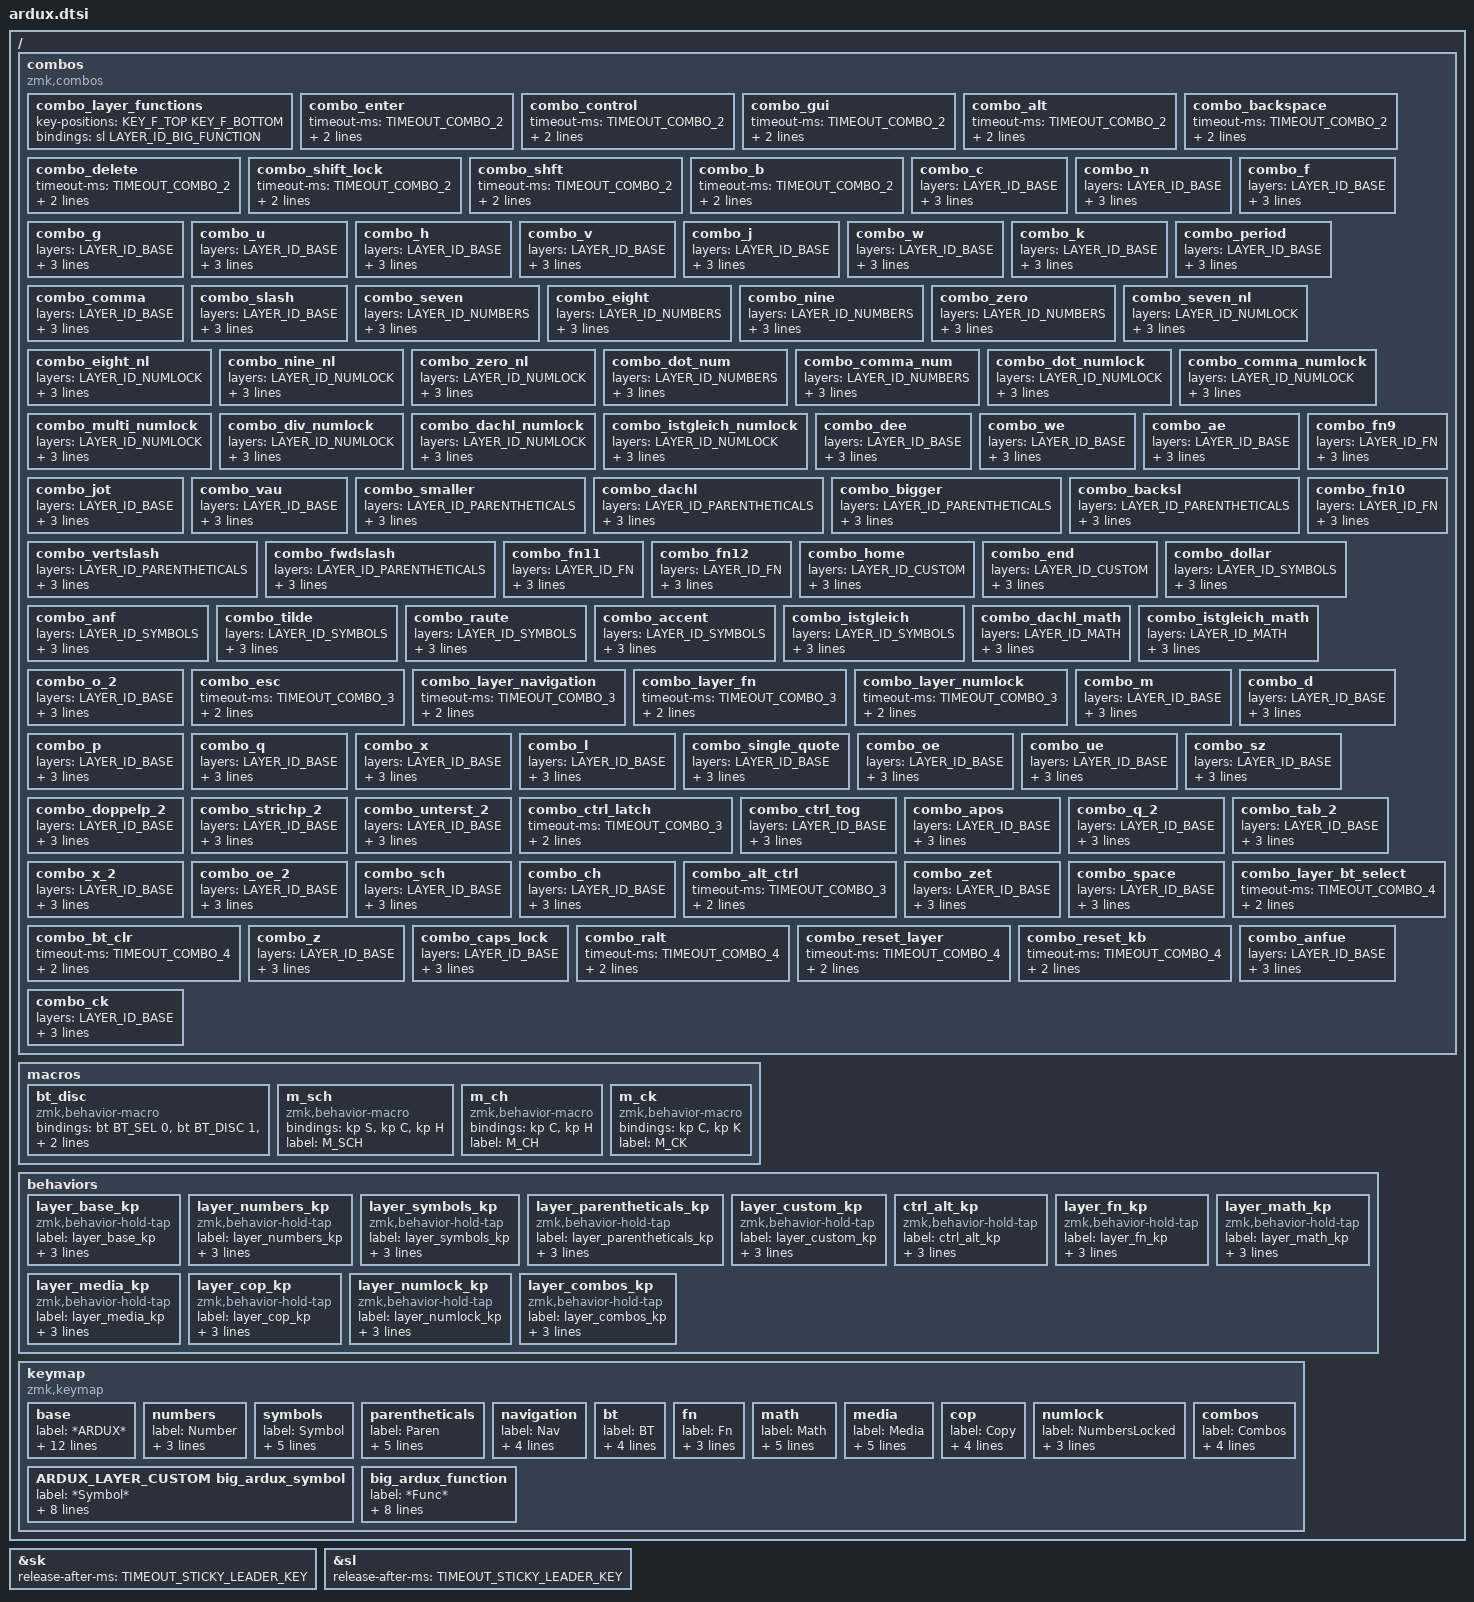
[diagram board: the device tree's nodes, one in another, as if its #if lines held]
/*
 * Copyright (c) 2021 Mike "KemoNine" Crosson
 *meins meins meins
 * SPDX-License-Identifier: MIT
 */

#include <behaviors.dtsi>
#include <dt-bindings/zmk/keys.h>
#include <dt-bindings/zmk/outputs.h>

/*****************************************
 * Macros for filling in "&none" in the right places in the keymap for re-use needs
 *****************************************/
#define NONE0(X)
#define NONE1(X) X
#define NONE2(X) NONE1(X) X
#define NONE3(X) NONE2(X) X
#define NONE4(X) NONE3(X) X
#define NONE5(X) NONE4(X) X
#define NONE6(X) NONE5(X) X
#define NONE7(X) NONE6(X) X
#define NONE8(X) NONE7(X) X
#define NONE9(X) NONE8(X) X
#define NONE10(X) NONE9(X) X

#define NONE(HUNDREDS,TENS,ONES) \
  NONE##HUNDREDS(NONE10(NONE10(&none))) \
  NONE##TENS(NONE10(&none)) \
  NONE##ONES(&none)

/*****************************************
 * ARDUX website : https://www.ardux.io
 * Primary reference : https://www.ardux.io/_FILES/images/ARDUX.jpg
*****************************************/

/*****************************************
 * Setting up ARDUX comboing
 *   - Enabled right OR left handed orientation
 *   - Please note: A/E key positions should be on your INDEX finger
 *     - The online reference is for right handed use
 *     - When using the ARDUX layout left handed you'll want to ensure your keypositions are flipped along the Y axis
 *   - Update/adjust the key positions using your boards keymap 
 *     - See below for additional details
 *   - YOU MUST SET THE FOLLOWING CONFIG VALUES FOR THIS SETUP TO WORK PROPERLY IN YOUR BOARDS .conf FILE
 *     - CONFIG_ZMK_COMBO_MAX_COMBOS_PER_KEY=16
 *     - CONFIG_ZMK_COMBO_MAX_KEYS_PER_COMBO=8
 *     - CONFIG_ZMK_COMBO_MAX_PRESSED_COMBOS=8
 *****************************************/

/*****************************************
 * Define which layout you want to use
 *  ONLY ENABLE ONE OF THESE
*****************************************/
//#define ARDUX_RIGHT 1
//#define ARDUX_LEFT 1
//#define ARDUX_BIG 1
// If you use COLEMAK as your standard keyboard layout, you may want this
//     This define will make base ardux keys and N more in line with COLEMAK
//#define ARDUX_COLEMAK 1

/*****************************************
 * Define key positions used for combos
 * These definitions are used to define the various ARDUX combos
 * 
 * Please see the documentation on "combos" for details on how to find the proper key positions
 *
 * Default key positions are for a generic 4x2 keyboard and should NOT be used outright
 * DEFINE these definitions in your boards keymap BEFORE including ardux.dtsi
*****************************************/
// ARTS Row
// #define KEY_A 0
// #define KEY_R 1
// #define KEY_T 2
// #define KEY_S 3
// EYIO Row
// #define KEY_E 4
// #define KEY_Y 5
// #define KEY_I 6
// #define KEY_O 7
// Big ardux F1-12 layer keys for combo
// #define KEY_F_TOP -1
// #define KEY_F_BOTTOM -1

/*****************************************
 * Define key position offsets in main keymap
 *
 * In order to make this keymap flexible, you must setup the number of &none "offsets" to use
 * The defines below should be set in your LOCAL keymap and using the above "NONE([hundreds],[tens],[ones])" macro for filling in the gaps
*****************************************/
// #define LEADING_NONES NONE(0, 1, 0)
// #define MIDDLE_NONES NONE(0, 0, 3)
// #define TRAILING_NONES NONE(0, 1, 0)
// #define BIG_LEADING_NONES NONE(0, 0, 0)
// #define BIG_BETWEEN_ROW_ONE_TWO_NONES NONE(0, 0, 0)
// #define BIG_BETWEEN_ROW_TWO_THREE_NONES NONE(0, 0, 0)
// #define BIG_BETWEEN_ROW_THREE_THUMBS NONE(0, 0, 0)
// #define BIG_TRAILING_NONES NONE(0, 0, 0)

/*****************************************
 * Define custom BT layer extra keys
 *
 * You can override the 2 blank keys on the BT select layer by copy/pasting the below into your keymap
 *     *before* including the ardux.dtsfile
 * Once added to your keymap you can adjust these 2 keys as you see fit
*****************************************/
#if !defined ARDUX_BT_TOP
#define ARDUX_BT_TOP &out OUT_BLE
#endif
#if !defined ARDUX_BT_BOTTOM
#define ARDUX_BT_BOTTOM &out OUT_USB
#endif

/*****************************************
 * Define how long it takes for the combos/holds to 'time out'
 * See documentation on "combos" for more detail
 * THE COMBO TIMEOUTS MUST BE THE SAME
 *    https://github.com/zmkfirmware/zmk/issues/905
 *****************************************/
#if !defined TIMEOUT_COMBO_2
#define TIMEOUT_COMBO_2 75
#endif
#if !defined TIMEOUT_COMBO_3
#define TIMEOUT_COMBO_3 125
#endif
#if !defined TIMEOUT_COMBO_4
#define TIMEOUT_COMBO_4 150
#endif
#if !defined TIMEOUT_LAYER_HOLD
#define TIMEOUT_LAYER_HOLD 200
#endif
#if !defined TIMEOUT_STICKY_LEADER_KEY
#define TIMEOUT_STICKY_LEADER_KEY 2500
#endif
&sk {
	release-after-ms = <TIMEOUT_STICKY_LEADER_KEY>;
};
&sl { 
	release-after-ms = <TIMEOUT_STICKY_LEADER_KEY>;
};

/*****************************************
 * Define custom layer
 *
 * You can override this layer by copy/pasting the into your keymap *before* including the ardux.dtsi file
 * Once added to your keymap you can adjust as you see fit
*****************************************/
#if !defined ARDUX_LAYER_CUSTOM
#if defined ARDUX_RIGHT
#define ARDUX_LAYER_CUSTOM                                            \
		custom {                                                       \
			label = "Custom";                                          \
			bindings = <                                               \
				LEADING_NONES                                          \
				&kp LC(LEFT)     &kp UP    &kp LC(RIGHT)  &none              \
				MIDDLE_NONES                                           \
				&kp LEFT     &kp DOWN  &kp RIGHT  &mo LAYER_ID_CUSTOM \
				TRAILING_NONES                                         \
			>;                                                         \
		};
		
#endif
#if defined ARDUX_LEFT
#define ARDUX_LAYER_CUSTOM                                            \
		custom {                                                       \
			label = "Custom";                                          \
			bindings = <                                               \
				LEADING_NONES                                          \
				&kp LC(RIGHT)     &kp UP   &kp LC(LEFT)   &none              \
				MIDDLE_NONES                                           \
				&kp RIGHT     &kp DOWN  &kp LEFT  &mo LAYER_ID_CUSTOM \
				TRAILING_NONES                                         \
			>;                                                         \
		};
#endif
#endif

/*****************************************
 * Define base layer chars for 'standard ARDUX' or 'COLEMAK' inspired (you can add more by following the pattern below)
 * Turn on the ARDUX_COLEMAK definition above if you want this change
 *****************************************/
#define ARDUX_BASE_A A
#define ARDUX_BASE_R T
#define ARDUX_BASE_T R
#define ARDUX_BASE_S D
#define ARDUX_BASE_E E
#define ARDUX_BASE_Y N
#define ARDUX_BASE_I I
#define ARDUX_BASE_O S
#define ARDUX_COMBO_N Z
#if ARDUX_COLEMAK
#define ARDUX_BASE_A T
#define ARDUX_BASE_R S
#define ARDUX_BASE_T R
#define ARDUX_BASE_S A
#define ARDUX_BASE_E N
#define ARDUX_BASE_Y E
#define ARDUX_BASE_I I
#define ARDUX_BASE_O O
#define ARDUX_COMBO_N Y
#endif

/*****************************************
 * Layer IDs used by the ARDUX keymap
 * Do NOT change these and do NOT change the order of the layers as shown below
 *****************************************/
#define LAYER_ID_GLOBAL -1
#define LAYER_ID_BASE 0
#define LAYER_ID_NUMBERS 1
#define LAYER_ID_SYMBOLS 2
#define LAYER_ID_PARENTHETICALS 3
#define LAYER_ID_NAVIGATION 4
#define LAYER_ID_BT_SEL 5
#define LAYER_ID_FN 6
#define LAYER_ID_MATH 7
#define LAYER_ID_MEDIA 8
#define LAYER_ID_COP 9
#define LAYER_ID_NUMLOCK 10
#define LAYER_ID_COMBOS 11
#define LAYER_ID_CUSTOM 12
#define LAYER_ID_BIG_SYM 13
#define LAYER_ID_BIG_FUNCTION 14



/*****************************************
 * Standard ARDUX combo definitions
 * These should NOT be changed and are global in scope
 *****************************************/
/ {
	combos {
		compatible = "zmk,combos";
		/*****************************************
		 * 2 key combos
		 *****************************************/
		// Function layer doesn't apply to non-big ardux presently
		#if defined ARDUX_BIG
		combo_layer_functions { key-positions = <KEY_F_TOP KEY_F_BOTTOM>; bindings = <&sl LAYER_ID_BIG_FUNCTION>; };
		#endif
		combo_enter      { timeout-ms = <TIMEOUT_COMBO_2>; key-positions = <KEY_A KEY_E>; bindings = <&kp ENTER>; };
		combo_control    { timeout-ms = <TIMEOUT_COMBO_2>; key-positions = <KEY_E KEY_S>; bindings = <&sk LCTRL>; };
		combo_gui        { timeout-ms = <TIMEOUT_COMBO_2>; key-positions = <KEY_Y KEY_S>; bindings = <&sk LGUI>; };
		combo_alt        { timeout-ms = <TIMEOUT_COMBO_2>; key-positions = <KEY_I KEY_S>; bindings = <&sk LALT>; };
		combo_backspace  { timeout-ms = <TIMEOUT_COMBO_2>; key-positions = <KEY_E KEY_R>; bindings = <&kp BACKSPACE>; };
		combo_delete     { timeout-ms = <TIMEOUT_COMBO_2>; key-positions = <KEY_I KEY_R>; bindings = <&kp DELETE>; };
		combo_shift_lock { timeout-ms = <TIMEOUT_COMBO_2>; key-positions = <KEY_R KEY_Y>; bindings = <&kt LSHFT>; };
		

		combo_shft        { timeout-ms = <TIMEOUT_COMBO_2>; key-positions = <KEY_T KEY_I>; bindings = <&sk LSHFT>; };

		combo_b           { timeout-ms = <TIMEOUT_COMBO_2>; key-positions = <KEY_E KEY_O>; bindings = <&kp SPACE>; };
		combo_c           { layers = <LAYER_ID_BASE>; timeout-ms = <TIMEOUT_COMBO_2>; key-positions = <KEY_E KEY_Y>; bindings = <&kp C>; };
		combo_n           { layers = <LAYER_ID_BASE>; timeout-ms = <TIMEOUT_COMBO_2>; key-positions = <KEY_I KEY_O>; bindings = <&kp ARDUX_COMBO_N>; };
		combo_f           { layers = <LAYER_ID_BASE>; timeout-ms = <TIMEOUT_COMBO_2>; key-positions = <KEY_A KEY_R>; bindings = <&kp F>; };
		combo_g           { layers = <LAYER_ID_BASE>; timeout-ms = <TIMEOUT_COMBO_2>; key-positions = <KEY_R KEY_T>; bindings = <&kp G>; };
		combo_u           { layers = <LAYER_ID_BASE>; timeout-ms = <TIMEOUT_COMBO_2>; key-positions = <KEY_Y KEY_I>; bindings = <&kp U>; };
		combo_h           { layers = <LAYER_ID_BASE>; timeout-ms = <TIMEOUT_COMBO_2>; key-positions = <KEY_E KEY_I>; bindings = <&kp H>; };
		combo_v           { layers = <LAYER_ID_BASE>; timeout-ms = <TIMEOUT_COMBO_2>; key-positions = <KEY_R KEY_S>; bindings = <&kp V>; };
		combo_j           { layers = <LAYER_ID_BASE>; timeout-ms = <TIMEOUT_COMBO_2>; key-positions = <KEY_T KEY_S>; bindings = <&kp J>; };
		combo_w           { layers = <LAYER_ID_BASE>; timeout-ms = <TIMEOUT_COMBO_2>; key-positions = <KEY_A KEY_S>; bindings = <&kp W>; };
		combo_k           { layers = <LAYER_ID_BASE>; timeout-ms = <TIMEOUT_COMBO_2>; key-positions = <KEY_Y KEY_O>; bindings = <&kp K>; };
		combo_period      { layers = <LAYER_ID_BASE>; timeout-ms = <TIMEOUT_COMBO_2>; key-positions = <KEY_A KEY_Y>; bindings = <&kp DOT>; };
		combo_comma       { layers = <LAYER_ID_BASE>; timeout-ms = <TIMEOUT_COMBO_2>; key-positions = <KEY_A KEY_I>; bindings = <&kp COMMA>; };
		combo_slash       { layers = <LAYER_ID_BASE>; timeout-ms = <TIMEOUT_COMBO_2>; key-positions = <KEY_A KEY_O>; bindings = <&kp SLASH>; };
		// combo_exclamation { layers = <LAYER_ID_BASE>; timeout-ms = <TIMEOUT_COMBO_2>; key-positions = <KEY_T KEY_I>; bindings = <&kp EXCL>; };
		//combo_apost       { layers = <LAYER_ID_BASE>; timeout-ms = <TIMEOUT_COMBO_2>; key-positions = <KEY_T KEY_E>; bindings = <&kp LS(NON_US_HASH)>; };
		
		combo_seven { layers = <LAYER_ID_NUMBERS>; timeout-ms = <TIMEOUT_COMBO_2>; key-positions = <KEY_A KEY_R>; bindings = <&kp N7>; };
		combo_eight { layers = <LAYER_ID_NUMBERS>; timeout-ms = <TIMEOUT_COMBO_2>; key-positions = <KEY_R KEY_T>; bindings = <&kp N8>; };
		combo_nine  { layers = <LAYER_ID_NUMBERS>; timeout-ms = <TIMEOUT_COMBO_2>; key-positions = <KEY_E KEY_Y>; bindings = <&kp N9>; };
		combo_zero  { layers = <LAYER_ID_NUMBERS>; timeout-ms = <TIMEOUT_COMBO_2>; key-positions = <KEY_Y KEY_I>; bindings = <&kp N0>; };

		combo_seven_nl { layers = <LAYER_ID_NUMLOCK>; timeout-ms = <TIMEOUT_COMBO_2>; key-positions = <KEY_A KEY_R>; bindings = <&kp N7>; };
		combo_eight_nl { layers = <LAYER_ID_NUMLOCK>; timeout-ms = <TIMEOUT_COMBO_2>; key-positions = <KEY_R KEY_T>; bindings = <&kp N8>; };
		combo_nine_nl  { layers = <LAYER_ID_NUMLOCK>; timeout-ms = <TIMEOUT_COMBO_2>; key-positions = <KEY_E KEY_Y>; bindings = <&kp N9>; };
		combo_zero_nl  { layers = <LAYER_ID_NUMLOCK>; timeout-ms = <TIMEOUT_COMBO_2>; key-positions = <KEY_Y KEY_I>; bindings = <&kp N0>; };

		combo_dot_num   { layers = <LAYER_ID_NUMBERS>; timeout-ms = <TIMEOUT_COMBO_2>; key-positions = <KEY_A KEY_T>; bindings = <&kp DOT>; };
		combo_comma_num { layers = <LAYER_ID_NUMBERS>; timeout-ms = <TIMEOUT_COMBO_2>; key-positions = <KEY_E KEY_I>; bindings = <&kp COMMA>; };

		combo_dot_numlock   { layers = <LAYER_ID_NUMLOCK>; timeout-ms = <TIMEOUT_COMBO_2>; key-positions = <KEY_A KEY_T>; bindings = <&kp DOT>; };
		combo_comma_numlock { layers = <LAYER_ID_NUMLOCK>; timeout-ms = <TIMEOUT_COMBO_2>; key-positions = <KEY_E KEY_I>; bindings = <&kp COMMA>; };
		combo_multi_numlock { layers = <LAYER_ID_NUMLOCK>; timeout-ms = <TIMEOUT_COMBO_2>; key-positions = <KEY_T KEY_S>; bindings = <&kp KP_MULTIPLY>; };
		combo_div_numlock { layers = <LAYER_ID_NUMLOCK>; timeout-ms = <TIMEOUT_COMBO_2>; key-positions = <KEY_I KEY_O>; bindings = <&kp KP_DIVIDE>; };
		combo_dachl_numlock { layers = <LAYER_ID_NUMLOCK>; timeout-ms = <TIMEOUT_COMBO_2>; key-positions = <KEY_R KEY_S>; bindings = <&kp GRAVE>; };
		combo_istgleich_numlock { layers = <LAYER_ID_NUMLOCK>; timeout-ms = <TIMEOUT_COMBO_2>; key-positions = <KEY_Y KEY_O>; bindings = <&kp LS(N0)>; };

		combo_dee     { layers = <LAYER_ID_BASE>; timeout-ms = <TIMEOUT_COMBO_2>; key-positions = <KEY_A KEY_T>; bindings = <&kp D>; };
		combo_we     { layers = <LAYER_ID_BASE>; timeout-ms = <TIMEOUT_COMBO_2>; key-positions = <KEY_E KEY_T>; bindings = <&kp W>; };
		combo_ae     { layers = <LAYER_ID_BASE>; timeout-ms = <TIMEOUT_COMBO_2>; key-positions = <KEY_Y KEY_T>; bindings = <&kp APOS>; };
		combo_jot     { layers = <LAYER_ID_BASE>; timeout-ms = <TIMEOUT_COMBO_2>; key-positions = <KEY_O KEY_T>; bindings = <&kp J>; };
		combo_vau     { layers = <LAYER_ID_BASE>; timeout-ms = <TIMEOUT_COMBO_2>; key-positions = <KEY_R KEY_O>; bindings = <&kp V>; };

		combo_smaller   { layers = <LAYER_ID_PARENTHETICALS>; timeout-ms = <TIMEOUT_COMBO_2>; key-positions = <KEY_R KEY_T>; bindings = <&kp NON_US_BACKSLASH>; };
		combo_dachl   { layers = <LAYER_ID_PARENTHETICALS>; timeout-ms = <TIMEOUT_COMBO_2>; key-positions = <KEY_R KEY_S>; bindings = <&kp GRAVE>; };
		combo_bigger   { layers = <LAYER_ID_PARENTHETICALS>; timeout-ms = <TIMEOUT_COMBO_2>; key-positions = <KEY_I KEY_Y>; bindings = <&kp LS(NON_US_BACKSLASH)>; };

		combo_backsl   { layers = <LAYER_ID_PARENTHETICALS>; timeout-ms = <TIMEOUT_COMBO_2>; key-positions = <KEY_I KEY_O>; bindings = <&kp RA(MINUS)>; };
		combo_vertslash   { layers = <LAYER_ID_PARENTHETICALS>; timeout-ms = <TIMEOUT_COMBO_2>; key-positions = <KEY_Y KEY_O>; bindings = <&kp RA(NON_US_BACKSLASH)>; };
		combo_fwdslash   { layers = <LAYER_ID_PARENTHETICALS>; timeout-ms = <TIMEOUT_COMBO_2>; key-positions = <KEY_T KEY_S>; bindings = <&kp LS(N7)>; };

		combo_fn9    { layers = <LAYER_ID_FN>; timeout-ms = <TIMEOUT_COMBO_2>; key-positions = <KEY_A KEY_R>; bindings = <&kp F9>; };
		combo_fn10   { layers = <LAYER_ID_FN>; timeout-ms = <TIMEOUT_COMBO_2>; key-positions = <KEY_R KEY_T>; bindings = <&kp F10>; };
		combo_fn11   { layers = <LAYER_ID_FN>; timeout-ms = <TIMEOUT_COMBO_2>; key-positions = <KEY_T KEY_S>; bindings = <&kp F11>; };
		combo_fn12   { layers = <LAYER_ID_FN>; timeout-ms = <TIMEOUT_COMBO_2>; key-positions = <KEY_E KEY_Y>; bindings = <&kp F12>; };


		#if defined ARDUX_RIGHT
		combo_home   { layers = <LAYER_ID_CUSTOM>; timeout-ms = <TIMEOUT_COMBO_2>; key-positions = <KEY_A KEY_R>; bindings = <&kp HOME>; };
		combo_end   { layers = <LAYER_ID_CUSTOM>; timeout-ms = <TIMEOUT_COMBO_2>; key-positions = <KEY_R KEY_T>; bindings = <&kp END>; };
		#endif
		#if defined ARDUX_LEFT
		combo_home   { layers = <LAYER_ID_CUSTOM>; timeout-ms = <TIMEOUT_COMBO_2>; key-positions = <KEY_T KEY_R>; bindings = <&kp HOME>; };
		combo_end   { layers = <LAYER_ID_CUSTOM>; timeout-ms = <TIMEOUT_COMBO_2>; key-positions = <KEY_R KEY_A>; bindings = <&kp END>; };
		#endif



		//combo_screen_mac   { layers = <LAYER_ID_ ???? >; timeout-ms = <TIMEOUT_COMBO_2>; key-positions = <KEY_E KEY_Y>; bindings = <&kp LG(LS(N3))>; };
		
		//combo_prev_track   { layers = <LAYER_ID_CUSTOM>; timeout-ms = <TIMEOUT_COMBO_2>; key-positions = <KEY_A KEY_R>; bindings = <&kp C_PREV>; };
		//combo_next_track   { layers = <LAYER_ID_CUSTOM>; timeout-ms = <TIMEOUT_COMBO_2>; key-positions = <KEY_R KEY_T>; bindings = <&kp C_NEXT>; };

		combo_dollar   { layers = <LAYER_ID_SYMBOLS>; timeout-ms = <TIMEOUT_COMBO_2>; key-positions = <KEY_R KEY_T>; bindings = <&kp LS(N4)>; };
		combo_anf   { layers = <LAYER_ID_SYMBOLS>; timeout-ms = <TIMEOUT_COMBO_2>; key-positions = <KEY_Y KEY_I>; bindings = <&kp LS(N3)>; };
		combo_tilde   { layers = <LAYER_ID_SYMBOLS>; timeout-ms = <TIMEOUT_COMBO_2>; key-positions = <KEY_T KEY_S>; bindings = <&kp RA(RIGHT_BRACKET)>; };
		combo_raute   { layers = <LAYER_ID_SYMBOLS>; timeout-ms = <TIMEOUT_COMBO_2>; key-positions = <KEY_I KEY_O>; bindings = <&kp NON_US_HASH>; };
		combo_accent   { layers = <LAYER_ID_SYMBOLS>; timeout-ms = <TIMEOUT_COMBO_2>; key-positions = <KEY_R KEY_S>; bindings = <&kp EQUAL >; };
		combo_istgleich   { layers = <LAYER_ID_SYMBOLS>; timeout-ms = <TIMEOUT_COMBO_2>; key-positions = <KEY_Y KEY_O>; bindings = <&kp LS(N0)>; };

		combo_dachl_math    { layers = <LAYER_ID_MATH>; timeout-ms = <TIMEOUT_COMBO_2>; key-positions = <KEY_A KEY_R>; bindings = <&kp GRAVE>; };
		combo_istgleich_math    { layers = <LAYER_ID_MATH>; timeout-ms = <TIMEOUT_COMBO_2>; key-positions = <KEY_E KEY_Y>; bindings = <&kp LS(N0)>; };

		combo_o_2           { layers = <LAYER_ID_BASE>; timeout-ms = <TIMEOUT_COMBO_2>; key-positions = <KEY_T KEY_O>; bindings = <&kp O>; };

		/*****************************************
		 * 3 key combos
		 *****************************************/
		combo_esc              { timeout-ms = <TIMEOUT_COMBO_3>; key-positions = <KEY_A KEY_R KEY_O>; bindings = <&kp ESC>; };
		combo_layer_navigation { timeout-ms = <TIMEOUT_COMBO_3>; key-positions = <KEY_R KEY_E KEY_I>; bindings = <&tog LAYER_ID_NAVIGATION>; };

		combo_layer_fn { timeout-ms = <TIMEOUT_COMBO_3>; key-positions = <KEY_A KEY_Y KEY_T>; bindings = <&sl LAYER_ID_FN>; };
		combo_layer_numlock { timeout-ms = <TIMEOUT_COMBO_3>; key-positions = <KEY_T KEY_Y KEY_O>; bindings = <&tog LAYER_ID_NUMLOCK>; };

		combo_m            { layers = <LAYER_ID_BASE>; timeout-ms = <TIMEOUT_COMBO_3>; key-positions = <KEY_Y KEY_I KEY_O>; bindings = <&kp M>; };
		combo_d            { layers = <LAYER_ID_BASE>; timeout-ms = <TIMEOUT_COMBO_3>; key-positions = <KEY_A KEY_R KEY_T>; bindings = <&kp O>; };
		combo_p            { layers = <LAYER_ID_BASE>; timeout-ms = <TIMEOUT_COMBO_3>; key-positions = <KEY_E KEY_I KEY_O>; bindings = <&kp P>; };
		combo_q            { layers = <LAYER_ID_BASE>; timeout-ms = <TIMEOUT_COMBO_3>; key-positions = <KEY_A KEY_T KEY_S>; bindings = <&kp Q>; };
		combo_x            { layers = <LAYER_ID_BASE>; timeout-ms = <TIMEOUT_COMBO_3>; key-positions = <KEY_R KEY_T KEY_S>; bindings = <&kp X>; };
		combo_l            { layers = <LAYER_ID_BASE>; timeout-ms = <TIMEOUT_COMBO_3>; key-positions = <KEY_E KEY_Y KEY_I>; bindings = <&kp L>; };
		combo_single_quote { layers = <LAYER_ID_BASE>; timeout-ms = <TIMEOUT_COMBO_3>; key-positions = <KEY_A KEY_Y KEY_I>; bindings = <&kp SQT>; };

		combo_oe            { layers = <LAYER_ID_BASE>; timeout-ms = <TIMEOUT_COMBO_3>; key-positions = <KEY_A KEY_R KEY_S>; bindings = <&kp SEMI>; };
		combo_ue            { layers = <LAYER_ID_BASE>; timeout-ms = <TIMEOUT_COMBO_3>; key-positions = <KEY_E KEY_Y KEY_O>; bindings = <&kp LBKT>; };
		combo_sz            { layers = <LAYER_ID_BASE>; timeout-ms = <TIMEOUT_COMBO_3>; key-positions = <KEY_R KEY_E KEY_O>; bindings = <&kp MINUS>; };
		//combo_doppelp       { layers = <LAYER_ID_BASE>; timeout-ms = <TIMEOUT_COMBO_3>; key-positions = <KEY_A KEY_R KEY_Y>; bindings = <&kp LS(DOT)>; };
		//combo_strichp       { layers = <LAYER_ID_BASE>; timeout-ms = <TIMEOUT_COMBO_3>; key-positions = <KEY_A KEY_T KEY_I>; bindings = <&kp LS(COMMA)>; };
		//combo_unterst       { layers = <LAYER_ID_BASE>; timeout-ms = <TIMEOUT_COMBO_3>; key-positions = <KEY_A KEY_S KEY_O>; bindings = <&kp LS(SLASH)>; };
		combo_doppelp_2     { layers = <LAYER_ID_BASE>; timeout-ms = <TIMEOUT_COMBO_3>; key-positions = <KEY_A KEY_E KEY_Y>; bindings = <&kp LS(DOT)>; };
		combo_strichp_2     { layers = <LAYER_ID_BASE>; timeout-ms = <TIMEOUT_COMBO_3>; key-positions = <KEY_A KEY_E KEY_I>; bindings = <&kp LS(COMMA)>; };
		combo_unterst_2     { layers = <LAYER_ID_BASE>; timeout-ms = <TIMEOUT_COMBO_3>; key-positions = <KEY_A KEY_E KEY_O>; bindings = <&kp LS(SLASH)>; };
                combo_ctrl_latch    { timeout-ms = <TIMEOUT_COMBO_3>; key-positions = <KEY_A KEY_S KEY_E>; bindings = <&kp LCTRL>; };
		combo_ctrl_tog      { layers = <LAYER_ID_BASE>; timeout-ms = <TIMEOUT_COMBO_3>; key-positions = <KEY_T KEY_S KEY_E>; bindings = <&kt LCTRL>; };
		combo_apos      { layers = <LAYER_ID_BASE>; timeout-ms = <TIMEOUT_COMBO_2>; key-positions = <KEY_T KEY_R KEY_E>; bindings = <&kp LS(NON_US_HASH)>; };


		combo_q_2           { layers = <LAYER_ID_BASE>; timeout-ms = <TIMEOUT_COMBO_3>; key-positions = <KEY_A KEY_T KEY_O>; bindings = <&kp Q>; };
		combo_tab_2         { layers = <LAYER_ID_BASE>; timeout-ms = <TIMEOUT_COMBO_3>; key-positions = <KEY_A KEY_R KEY_I>; bindings = <&kp TAB>; };
		combo_x_2            { layers = <LAYER_ID_BASE>; timeout-ms = <TIMEOUT_COMBO_3>; key-positions = <KEY_R KEY_T KEY_O>; bindings = <&kp X>; };
		combo_oe_2            { layers = <LAYER_ID_BASE>; timeout-ms = <TIMEOUT_COMBO_3>; key-positions = <KEY_T KEY_E KEY_Y>; bindings = <&kp SEMI>; };

		combo_sch           { layers = <LAYER_ID_BASE>; timeout-ms = <TIMEOUT_COMBO_3>; key-positions = <KEY_R KEY_I KEY_O>; bindings = <&m_sch>; };
		combo_ch           { layers = <LAYER_ID_BASE>; timeout-ms = <TIMEOUT_COMBO_3>; key-positions = <KEY_A KEY_I KEY_O>; bindings = <&m_ch>; };

		combo_alt_ctrl        { timeout-ms = <TIMEOUT_COMBO_3>; key-positions = <KEY_E KEY_I KEY_S>; bindings = <&sk LC(LALT)>; };

		/*****************************************
		 * 4 key combos
		 *****************************************/
		combo_zet             { layers = <LAYER_ID_BASE>; timeout-ms = <TIMEOUT_COMBO_4>; key-positions = <KEY_A KEY_R KEY_T KEY_O>; bindings = <&kp Y>; };
		combo_space           {  layers = <LAYER_ID_BASE>; timeout-ms = <TIMEOUT_COMBO_4>; key-positions = <KEY_E KEY_Y KEY_I KEY_O>; bindings = <&kp B>; };
		// combo_shift           { timeout-ms = <TIMEOUT_COMBO_4>; key-positions = <KEY_E KEY_R KEY_T KEY_S>; bindings = <&sk LSHFT>; };
		combo_layer_bt_select { timeout-ms = <TIMEOUT_COMBO_4>; key-positions = <KEY_A KEY_E KEY_S KEY_O>; bindings = <&sl LAYER_ID_BT_SEL>; };
		combo_bt_clr          { timeout-ms = <TIMEOUT_COMBO_4>; key-positions = <KEY_R KEY_Y KEY_T KEY_I>; bindings = <&bt BT_CLR>; };

		combo_z         { layers = <LAYER_ID_BASE>; timeout-ms = <TIMEOUT_COMBO_4>; key-positions = <KEY_A KEY_R KEY_T KEY_S>; bindings = <&kp Y>; };
		combo_caps_lock { layers = <LAYER_ID_BASE>; timeout-ms = <TIMEOUT_COMBO_4>; key-positions = <KEY_O KEY_I KEY_Y KEY_A>; bindings = <&kp CAPS>; };

		combo_ralt           { timeout-ms = <TIMEOUT_COMBO_4>; key-positions = <KEY_E KEY_R KEY_T KEY_S>; bindings = <&sk RALT>; };
		combo_reset_layer       { timeout-ms = <TIMEOUT_COMBO_4>; key-positions = <KEY_E KEY_R KEY_T KEY_O>; bindings = <&to LAYER_ID_BASE>; };
		combo_reset_kb       { timeout-ms = <TIMEOUT_COMBO_4>; key-positions = <KEY_A KEY_S KEY_Y KEY_I>; bindings = <&sys_reset>; };

		combo_anfue      { layers = <LAYER_ID_BASE>; timeout-ms = <TIMEOUT_COMBO_4>; key-positions = <KEY_A KEY_R KEY_T KEY_E>; bindings = <&kp LS(N2)>; };

		combo_ck           { layers = <LAYER_ID_BASE>; timeout-ms = <TIMEOUT_COMBO_4>; key-positions = <KEY_A KEY_R KEY_I KEY_O>; bindings = <&m_ck>; };
 		/**************************************
		* eigenes
		****************************************/
		// combo_boot          { timeout-ms = <TIMEOUT_COMBO_4>; key-positions = <KEY_R KEY_T KEY_E KEY_O>; bindings = <&bootloader>; };
	};

	macros {

       	 bt_disc: bt_disc {
            compatible = "zmk,behavior-macro";
            #binding-cells = <0>;
            bindings = <&bt BT_SEL 0 &bt BT_DISC 1 &bt BT_DISC 2>;
	    // bindings = <&bt BT_SEL 0>;
            label = "BT_DISC";
        };

	m_sch: m_sch {
            compatible = "zmk,behavior-macro";
            #binding-cells = <0>;
            bindings = <&kp S &kp C &kp H>;
            label = "M_SCH";
        };
	m_ch: m_ch {
            compatible = "zmk,behavior-macro";
            #binding-cells = <0>;
            bindings = <&kp C &kp H>;
            label = "M_CH";
        };
	m_ck: m_ck {
            compatible = "zmk,behavior-macro";
            #binding-cells = <0>;
            bindings = <&kp C &kp K>;
            label = "M_CK";
        };
    };



};







/*****************************************
 * Standard ARDUX layer activation definitions
 * These should NOT be changed and are global in scope
 *****************************************/
/ {
	behaviors {
		layer_base_kp: layer_base_kp { compatible = "zmk,behavior-hold-tap"; label = "layer_base_kp"; 
						#binding-cells = <2>; tapping_term_ms = <TIMEOUT_LAYER_HOLD>; flavor = "tap-preferred"; 
						bindings = <&mo>, <&kp>; };
		layer_numbers_kp: layer_numbers_kp { compatible = "zmk,behavior-hold-tap"; label = "layer_numbers_kp"; 
						#binding-cells = <2>; tapping_term_ms = <TIMEOUT_LAYER_HOLD>; flavor = "tap-preferred"; 
						bindings = <&mo>, <&kp>; };
		layer_symbols_kp: layer_symbols_kp { compatible = "zmk,behavior-hold-tap"; label = "layer_symbols_kp"; 
						#binding-cells = <2>; tapping_term_ms = <TIMEOUT_LAYER_HOLD>; flavor = "tap-preferred"; 
						bindings = <&mo>, <&kp>; };
		layer_parentheticals_kp: layer_parentheticals_kp { compatible = "zmk,behavior-hold-tap"; label = "layer_parentheticals_kp";
						#binding-cells = <2>; tapping_term_ms = <TIMEOUT_LAYER_HOLD>; flavor = "tap-preferred";
						bindings = <&mo>, <&kp>; };
		layer_custom_kp: layer_custom_kp { compatible = "zmk,behavior-hold-tap"; label = "layer_custom_kp";
						#binding-cells = <2>; tapping_term_ms = <TIMEOUT_LAYER_HOLD>; flavor = "tap-preferred";
						bindings = <&mo>, <&kp>; };
		ctrl_alt_kp: ctrl_alt_kp { compatible = "zmk,behavior-hold-tap"; label = "ctrl_alt_kp";
						#binding-cells = <2>; tapping_term_ms = <TIMEOUT_LAYER_HOLD>; flavor = "tap-preferred";
						bindings = <&sk>, <&sk>; };

		layer_fn_kp: layer_fn_kp { compatible = "zmk,behavior-hold-tap"; label = "layer_fn_kp";
						#binding-cells = <2>; tapping_term_ms = <TIMEOUT_LAYER_HOLD>; flavor = "tap-preferred";
						bindings = <&mo>, <&kp>; };
		layer_math_kp: layer_math_kp { compatible = "zmk,behavior-hold-tap"; label = "layer_math_kp";
						#binding-cells = <2>; tapping_term_ms = <TIMEOUT_LAYER_HOLD>; flavor = "tap-preferred";
						bindings = <&mo>, <&kp>; };
		layer_media_kp: layer_media_kp { compatible = "zmk,behavior-hold-tap"; label = "layer_media_kp";
						#binding-cells = <2>; tapping_term_ms = <TIMEOUT_LAYER_HOLD>; flavor = "tap-preferred";
						bindings = <&mo>, <&kp>; };
		layer_cop_kp: layer_cop_kp { compatible = "zmk,behavior-hold-tap"; label = "layer_cop_kp";
						#binding-cells = <2>; tapping_term_ms = <TIMEOUT_LAYER_HOLD>; flavor = "tap-preferred";
						bindings = <&mo>, <&kp>; };
		layer_numlock_kp: layer_numlock_kp { compatible = "zmk,behavior-hold-tap"; label = "layer_numlock_kp";
						#binding-cells = <2>; tapping_term_ms = <TIMEOUT_LAYER_HOLD>; flavor = "tap-preferred";
						bindings = <&mo>, <&kp>; };
		layer_combos_kp: layer_combos_kp { compatible = "zmk,behavior-hold-tap"; label = "layer_combos_kp";
						#binding-cells = <2>; tapping_term_ms = <TIMEOUT_LAYER_HOLD>; flavor = "tap-preferred";
						bindings = <&mo>, <&kp>; };
	};
};

/*****************************************
 * Standard ARDUX layer definitions
 * !!!!!!!!!! FOR RIGHT HANDED USE !!!!!!!!!!
 *****************************************/
#if defined ARDUX_RIGHT
/ {
	keymap {
		compatible = "zmk,keymap";
		#if defined ARDUX_BIG
		base {
			label = "*ARDUX*";
			bindings = <
				BIG_LEADING_NONES
				&kp MINUS            &layer_parentheticals_kp LAYER_ID_PARENTHETICALS ARDUX_BASE_A    &kp ARDUX_BASE_R     &kp ARDUX_BASE_T     &layer_numbers_kp LAYER_ID_NUMBERS ARDUX_BASE_S
				BIG_BETWEEN_ROW_ONE_TWO_NONES
				&sk LSHFT            &layer_symbols_kp LAYER_ID_SYMBOLS ARDUX_BASE_E                  &kp ARDUX_BASE_Y     &kp ARDUX_BASE_I     &layer_custom_kp LAYER_ID_CUSTOM ARDUX_BASE_O
				BIG_BETWEEN_ROW_TWO_THREE_NONES
				&kp TAB              &kp EQUAL                                                         &kp DEL               &kp AT                &ctrl_alt_kp LALT LCTRL
				BIG_BETWEEN_ROW_THREE_THUMBS
				&kp ENTER            &kp SPACE                                                         &mo LAYER_ID_BIG_SYM
				BIG_TRAILING_NONES
			>;
		};
		#else
		base {
			label = "ARDUX";
			bindings = <
				LEADING_NONES
				&layer_parentheticals_kp LAYER_ID_PARENTHETICALS ARDUX_BASE_A  &layer_combos_kp LAYER_ID_COMBOS ARDUX_BASE_R     &layer_math_kp LAYER_ID_MATH ARDUX_BASE_T     &layer_numbers_kp LAYER_ID_NUMBERS ARDUX_BASE_S
				MIDDLE_NONES
				&layer_symbols_kp LAYER_ID_SYMBOLS ARDUX_BASE_E                &layer_media_kp LAYER_ID_MEDIA ARDUX_BASE_Y     &layer_cop_kp LAYER_ID_COP ARDUX_BASE_I     &layer_custom_kp LAYER_ID_CUSTOM ARDUX_BASE_O
				TRAILING_NONES
				#if defined CUSTOM_THUMB
				CUSTOM_THUMB
				#endif
			>;
		};
		#endif
		numbers {
			label = "Number";
			bindings = <
				LEADING_NONES
				&kp N1                                              &kp N2    &kp N3    &mo LAYER_ID_NUMBERS
				MIDDLE_NONES
				&kp N4                                              &kp N5    &kp N6    &kp N0
				TRAILING_NONES
			>;
		};
		symbols {
			label = "Symbol";
			bindings = <
				LEADING_NONES
				&kp LS(GRAVE)                                            &kp LS(NUMBER_1)  &kp RA(E)  &kp LS(N5) 
				MIDDLE_NONES
				&mo LAYER_ID_SYMBOLS                                &kp LS(MINUS) &kp RA (Q)  &kp LS(N6)
				TRAILING_NONES
			>;
		};
		parentheticals {
			label = "Paren";
			bindings = <
				LEADING_NONES
				&mo LAYER_ID_PARENTHETICALS                         &kp LS(N8)  &kp RA(N8) &kp RA(N7)
				MIDDLE_NONES
				&none                                                &kp LS(N9)   &kp RA(N9)   &kp RA(N0) 
				TRAILING_NONES
			>;
		};
		navigation {
			label = "Nav";
			bindings = <
				LEADING_NONES
				&kp LC(LEFT)                                            &kp UP    &kp LC(RIGHT)   &kp PG_UP
				MIDDLE_NONES
				&kp LEFT                                            &kp DOWN  &kp RIGHT &kp PG_DN
				TRAILING_NONES
			>;
		};
		bt {
			label = "BT";
			bindings = <
				LEADING_NONES
				&bt_disc &bt BT_SEL 1 &bt BT_SEL 2 ARDUX_BT_TOP
				MIDDLE_NONES
				&bt BT_SEL 3 &bt BT_SEL 4 &bootloader ARDUX_BT_BOTTOM
				TRAILING_NONES
			>;
		};
		fn {
			label = "Fn";
			bindings = <
				LEADING_NONES
				&kp F1 &kp F2 &kp F3 &kp F4
				MIDDLE_NONES
				&kp F5 &kp F6 &kp F7 &kp F8
				TRAILING_NONES
			>;
		};
		math {
			label = "Math";
			bindings = <
				LEADING_NONES
				&kp KP_PLUS                        &kp KP_MULTIPLY  &mo LAYER_ID_MATH  &kp LC(KP_PLUS)
				MIDDLE_NONES
				&kp KP_MINUS                      &kp KP_DIVIDE   &none   &kp LC(KP_MINUS) 
				TRAILING_NONES
			>;
		};
		media {
			label = "Media";
			bindings = <
				LEADING_NONES
				&kp C_VOL_UP                        &kp C_PLAY  &kp C_NEXT  &kp RS(DOT)
				MIDDLE_NONES
				&kp C_VOL_DN                      &mo LAYER_ID_MEDIA   &kp C_PREV   &kp RS(COMMA)  
				TRAILING_NONES
			>;
		};
		cop {
			label = "Copy";
			bindings = <
				LEADING_NONES
				&kp LC(C)                       &kp LC(V)  &kp LG(LS(N3))  &kp PRINTSCREEN
				MIDDLE_NONES
				&kp LC(X)                      &kp LC(Y)   &mo LAYER_ID_COP   &kp LC(LS(Y)) 
				TRAILING_NONES
			>;
		};
		numlock {
			label = "NumbersLocked";
			bindings = <
				LEADING_NONES
				&kp N1                                              &kp N2    &kp N3    &kp KP_PLUS 
				MIDDLE_NONES
				&kp N4                                              &kp N5    &kp N6    &kp KP_MINUS 
				TRAILING_NONES
			>;
		};
		combos {
			label = "Combos";
			bindings = <
				LEADING_NONES
				&kp LG(LC(A)) &mo LAYER_ID_COMBOS &kp F8 &kp F9
				MIDDLE_NONES
				&kp LG(LC(E)) &kp LG(N) &kp F10 &kp F11
				TRAILING_NONES
			>;
		};
		ARDUX_LAYER_CUSTOM
		#if defined ARDUX_BIG
		big_ardux_symbol {
			label = "*Symbol*";
			bindings = <
				BIG_LEADING_NONES
				&kp GRAVE &kp HASH  &kp LBRC &kp RBRC &kp CARET
				BIG_BETWEEN_ROW_ONE_TWO_NONES
				&kp BSLH  &kp DLLR  &kp LPAR &kp RPAR &kp AMPS
				BIG_BETWEEN_ROW_TWO_THREE_NONES
				&kp PIPE  &kp PRCNT &kp LBKT &kp RBKT &kp ASTRK
				BIG_BETWEEN_ROW_THREE_THUMBS
				&trans    &kp SEMI  &none
				BIG_TRAILING_NONES
			>;
		};
		big_ardux_function {
			label = "*Func*";
			bindings = <
				BIG_LEADING_NONES
				&none  &kp F1 &kp F2  &kp F3  &kp F4
				BIG_BETWEEN_ROW_ONE_TWO_NONES
				&none  &kp F5 &kp F6  &kp F7  &kp F8
				BIG_BETWEEN_ROW_TWO_THREE_NONES
				&none  &kp F9 &kp F10 &kp F11 &kp F12
				BIG_BETWEEN_ROW_THREE_THUMBS
				&trans &none   &none
				BIG_TRAILING_NONES
			>;
		};
		#endif

	};
};
#endif

/*****************************************
 * Standard ARDUX layer definitions
 * !!!!!!!!!! FOR LEFT HANDED USE !!!!!!!!!!
 *****************************************/
#if defined ARDUX_LEFT
/ {
	keymap {
		compatible = "zmk,keymap";
		#if defined ARDUX_BIG
		base {
			label = "*ARDUX*";
			bindings = <
				BIG_LEADING_NONES
				&kp MINUS            &layer_parentheticals_kp LAYER_ID_PARENTHETICALS ARDUX_BASE_A    &kp ARDUX_BASE_R     &kp ARDUX_BASE_T     &layer_numbers_kp LAYER_ID_NUMBERS ARDUX_BASE_S
				BIG_BETWEEN_ROW_ONE_TWO_NONES
				&sk LSHFT            &layer_symbols_kp LAYER_ID_SYMBOLS ARDUX_BASE_E                  &kp ARDUX_BASE_Y     &kp ARDUX_BASE_I     &layer_custom_kp LAYER_ID_CUSTOM ARDUX_BASE_O
				BIG_BETWEEN_ROW_TWO_THREE_NONES
				&kp TAB              &kp EQUAL                                                         &kp DEL               &kp AT                &ctrl_alt_kp LALT LCTRL
				BIG_BETWEEN_ROW_THREE_THUMBS
				&kp ENTER            &kp SPACE                                                         &mo LAYER_ID_BIG_SYM
				BIG_TRAILING_NONES
			>;
		};
		#else
		base {
			label = "ARDUX";
			bindings = <
				LEADING_NONES
				&layer_parentheticals_kp LAYER_ID_PARENTHETICALS ARDUX_BASE_A  &layer_combos_kp LAYER_ID_COMBOS ARDUX_BASE_R     &layer_math_kp LAYER_ID_MATH ARDUX_BASE_T     &layer_numbers_kp LAYER_ID_NUMBERS ARDUX_BASE_S
				MIDDLE_NONES
				&layer_symbols_kp LAYER_ID_SYMBOLS ARDUX_BASE_E                &layer_media_kp LAYER_ID_MEDIA ARDUX_BASE_Y     &layer_cop_kp LAYER_ID_COP ARDUX_BASE_I     &layer_custom_kp LAYER_ID_CUSTOM ARDUX_BASE_O
				TRAILING_NONES
				#if defined CUSTOM_THUMB
				CUSTOM_THUMB
				#endif
			>;
		};
		#endif
		numbers {
			label = "Number";
			bindings = <
				LEADING_NONES
				&kp N1                                              &kp N2    &kp N3    &mo LAYER_ID_NUMBERS
				MIDDLE_NONES
				&kp N4                                              &kp N5    &kp N6    &kp N0
				TRAILING_NONES
			>;
		};
		symbols {
			label = "Symbol";
			bindings = <
				LEADING_NONES
				&kp LS(GRAVE)                                            &kp LS(NUMBER_1)  &kp RA(E)  &kp LS(N5) 
				MIDDLE_NONES
				&mo LAYER_ID_SYMBOLS                                &kp LS(MINUS) &kp RA (Q) &kp LS(N6)
				TRAILING_NONES
			>;
		};
		parentheticals {
			label = "Paren";
			bindings = <
				LEADING_NONES
				&mo LAYER_ID_PARENTHETICALS                         &kp LS(N8)  &kp RA(N8) &kp RA(N7)
				MIDDLE_NONES
				&none                                                &kp LS(N9)   &kp RA(N9)   &kp RA(N0) 
				TRAILING_NONES
			>;
		};
		navigation {
			label = "Nav";
			bindings = <
				LEADING_NONES
				&kp LC(RIGHT)                                            &kp UP    &kp LC(LEFT)   &kp PG_UP
				MIDDLE_NONES
				&kp RIGHT                                           &kp DOWN  &kp LEFT  &kp PG_DN
				TRAILING_NONES
			>;
		};
		bt {
			label = "BT";
			bindings = <
				LEADING_NONES
				&bt_disc &bt BT_SEL 1 &bt BT_SEL 2 ARDUX_BT_TOP
				MIDDLE_NONES
				&bt BT_SEL 3 &bt BT_SEL 4 &bootloader ARDUX_BT_BOTTOM
				TRAILING_NONES
			>;
		};
		fn {
			label = "Fn";
			bindings = <
				LEADING_NONES
				&kp F1 &kp F2 &kp F3 &kp F4
				MIDDLE_NONES
				&kp F5 &kp F6 &kp F7 &kp F8
				TRAILING_NONES
			>;
		};
		math {
			label = "Math";
			bindings = <
				LEADING_NONES
				&kp KP_PLUS                        &kp KP_MULTIPLY  &mo LAYER_ID_MATH  &kp LC(KP_PLUS)
				MIDDLE_NONES
				&kp KP_MINUS                      &kp KP_DIVIDE   &none   &kp LC(KP_MINUS) 
				TRAILING_NONES
			>;
		};
		media {
			label = "Media";
			bindings = <
				LEADING_NONES
				&kp C_VOL_UP                        &kp C_PLAY  &kp C_NEXT  &kp RS(DOT)
				MIDDLE_NONES
				&kp C_VOL_DN                      &mo LAYER_ID_MEDIA   &kp C_PREV   &kp RS(COMMA) 
				TRAILING_NONES
			>;
		};
		cop {
			label = "Copy";
			bindings = <
				LEADING_NONES
				&kp LC(C)                       &kp LC(V)  &kp LG(LS(N3))  &kp PRINTSCREEN
				MIDDLE_NONES
				&kp LC(X)                      &kp LC(Y)   &mo LAYER_ID_COP   &kp LC(LS(Y)) 
				TRAILING_NONES
			>;
		};
		numlock {
			label = "NumbersLocked";
			bindings = <
				LEADING_NONES
				&kp N1                                              &kp N2    &kp N3    &kp KP_PLUS 
				MIDDLE_NONES
				&kp N4                                              &kp N5    &kp N6    &kp KP_MINUS 
				TRAILING_NONES
			>;
		};
		combos {
			label = "Combos";
			bindings = <
				LEADING_NONES
				&kp LG(LC(A)) &mo LAYER_ID_COMBOS &kp F8 &kp F9
				MIDDLE_NONES
				&kp LG(LC(E)) &kp LG(N) &kp F10 &kp F11
				TRAILING_NONES
			>;
		};
		ARDUX_LAYER_CUSTOM
		#if defined ARDUX_BIG
		big_ardux_symbol {
			label = "*Symbol*";
			bindings = <
				BIG_LEADING_NONES
				&kp CARET &kp LBRC &kp RBRC &kp HASH  &kp GRAVE
				BIG_BETWEEN_ROW_ONE_TWO_NONES
				&kp AMPS  &kp LPAR &kp RPAR &kp DLLR  &kp BSLH
				BIG_BETWEEN_ROW_TWO_THREE_NONES
				&kp ASTRK &kp LBKT &kp RBKT &kp PRCNT &kp PIPE
				BIG_BETWEEN_ROW_THREE_THUMBS
				&none     &kp SEMI &none
				BIG_TRAILING_NONES
			>;
		};
		big_ardux_function {
			label = "*Func*";
			bindings = <
				BIG_LEADING_NONES
				&kp F4  &kp F3  &kp F2  &kp F1  &none
				BIG_BETWEEN_ROW_ONE_TWO_NONES
				&kp F8  &kp F7  &kp F6  &kp F5  &none
				BIG_BETWEEN_ROW_TWO_THREE_NONES
				&kp F12 &kp F11 &kp F10 &kp F9 &none
				BIG_BETWEEN_ROW_THREE_THUMBS
				&none   &none   &none
				BIG_TRAILING_NONES
			>;
		};
		#endif
	};
};
#endif
